# f28p65x_escss_regs register map
Vendor: Texas Instruments
Peripheral module from a debugger description file (folder C2000).
Address unit: 16 bits
Registers are 32-bit, read-write, no defined reset value unless marked. A register's access mark holds for its fields unless they carry their own. Offsets are as the file gives them; lines under a group give offsets from that group; [hi:lo] are bit positions; {n}, {i} and the like mark numbered series; 'fields as' and 'values as' point back to an identical list; <NAME> marks a mode.

## ESCSS_REGS — ESCSS Registers
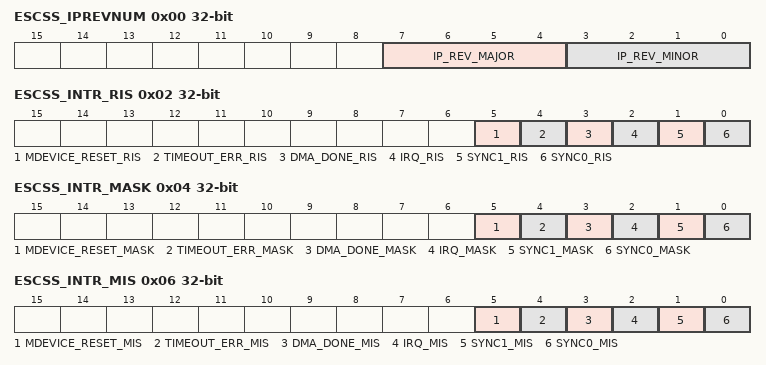
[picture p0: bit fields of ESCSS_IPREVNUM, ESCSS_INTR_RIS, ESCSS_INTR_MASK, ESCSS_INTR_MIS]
0x00 ESCSS_IPREVNUM ro — IP Revision Number
  [7:4] IP_REV_MAJOR — Major IP Revision Number
  [3:0] IP_REV_MINOR — Minor IP Revision Number
0x02 ESCSS_INTR_RIS ro — EtherCATSS Interrupt Raw Status
  [5] MDEVICE_RESET_RIS — ECAT RESET RIS
  [4] TIMEOUT_ERR_RIS — PDI bus Timeout Error RIS
  [3] DMA_DONE_RIS
  [2] IRQ_RIS — EtherCATSS IRQ RIS
  [1] SYNC1_RIS — SYNC1 feature RIS
  [0] SYNC0_RIS — SYNC0 feature RIS
0x04 ESCSS_INTR_MASK — EtherCATSS Interrupt Mask
  [5] MDEVICE_RESET_MASK — EtherCAT MainDevice Reset Mask
  [4] TIMEOUT_ERR_MASK — PDI Access Timeout Error Mask
  [3] DMA_DONE_MASK
  [2] IRQ_MASK — EtherCATSS IRQ Mask
  [1] SYNC1_MASK — SYNC1 feature Mask
  [0] SYNC0_MASK — SYNC0 feature Mask
0x06 ESCSS_INTR_MIS ro — EtherCATSS Masked Interrupt Status
  [5] MDEVICE_RESET_MIS — EtherCAT MainDevice Reset MIS
  [4] TIMEOUT_ERR_MIS — PDI bus Timeout Error MIS
  [3] DMA_DONE_MIS
  [2] IRQ_MIS — EtherCATSS IRQ MIS
  [1] SYNC1_MIS — SYNC1 feature MIS
  [0] SYNC0_MIS — SYNC0 feature MIS
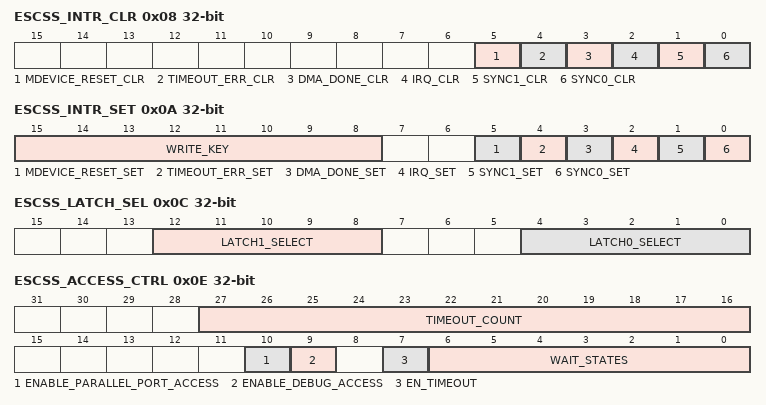
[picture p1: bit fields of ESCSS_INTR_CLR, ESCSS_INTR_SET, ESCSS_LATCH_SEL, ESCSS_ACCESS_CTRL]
0x08 ESCSS_INTR_CLR — EtherCATSS Interrupt Clear
  [5] MDEVICE_RESET_CLR — EtherCAT MainDevice Reset Clear
  [4] TIMEOUT_ERR_CLR — PDI Access Timeout Error Clear
  [3] DMA_DONE_CLR — DMA Done Clear
  [2] IRQ_CLR — EtherCATSS IRQ Clear
  [1] SYNC1_CLR — SYNC1 feature Clear
  [0] SYNC0_CLR — SYNC0 feature Clear
0x0A ESCSS_INTR_SET — EtherCATSS Interrupt Set to emulate
  [15:8] WRITE_KEY — Key to enable writing lock
  [5] MDEVICE_RESET_SET — EtherCAT MainDevice Reset Emulate
  [4] TIMEOUT_ERR_SET — PDI Access Timeout Error Set Emulate
  [3] DMA_DONE_SET — DMA Done Set Emulate
  [2] IRQ_SET — EtherCATSS IRQ Set Emulate
  [1] SYNC1_SET — SYNC1 Set Emulate
  [0] SYNC0_SET — SYNC0 Set Emulate
0x0C ESCSS_LATCH_SEL — Select for Latch0/1 inputs and LATCHIN input
  [12:8] LATCH1_SELECT — LATCH1 Inputs mux select
  [4:0] LATCH0_SELECT — LATCH0 Inputs mux select
0x0E ESCSS_ACCESS_CTRL — PDI interface access control config.
  [27:16] TIMEOUT_COUNT — Max timecount programmed and count while enabled.
  [10] ENABLE_PARALLEL_PORT_ACCESS — Parallel port access enable
  [9] ENABLE_DEBUG_ACCESS — Debug access enable
  [7] EN_TIMEOUT — PDI Timeout enable
  [6:0] WAIT_STATES — Minimum Wait States for VBUS Bridge
0x10 ESCSS_GPIN_DAT — GPIN data capture for debug and override
  [31:0] GPIN_DAT — Registered GPI data driving EtherCAT GPI input
0x12 ESCSS_GPIN_PIPE — GPIN pipeline select
  [31:0] GPI_PIPE — GPI IO inputs pipeline enable.
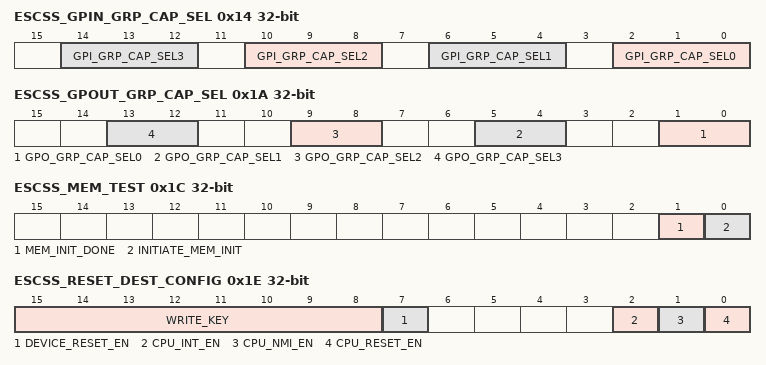
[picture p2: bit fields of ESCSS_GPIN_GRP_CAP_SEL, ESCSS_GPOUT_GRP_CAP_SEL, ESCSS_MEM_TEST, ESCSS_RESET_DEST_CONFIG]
0x14 ESCSS_GPIN_GRP_CAP_SEL — GPIN pipe group capture trigger
  [4n+2:4n] GPI_GRP_CAP_SEL{n} (n=0..3) — GPI{8n+7}-{8n} capture trigger select
0x16 ESCSS_GPOUT_DAT ro — GPOUT data capture for debug and override
  [31:0] GPOUT_DAT — Registered GPO data from EtherCAT o/p
0x18 ESCSS_GPOUT_PIPE — GPOUT pipeline select
  [31:0] GPO_PIPE — GPO output pipeline enable.
0x1A ESCSS_GPOUT_GRP_CAP_SEL — GPOUT pipe group capture trigger
  [4n+1:4n] GPO_GRP_CAP_SEL{n} (n=0..3) — GPO{8n+7}-{8n} capture trigger select
0x1C ESCSS_MEM_TEST access per field — Memory Test Control
  [1] MEM_INIT_DONE ro — Memory Init done status
  [0] INITIATE_MEM_INIT rw — Initialize memory init
0x1E ESCSS_RESET_DEST_CONFIG — ResetOut impact or destination config
  [15:8] WRITE_KEY — Key to enable writing lock
  [7] DEVICE_RESET_EN — Enables RESET_OUT to impact the device reset
  [2] CPU_INT_EN — CPU Interrupt enable for ResetOut
  [1] CPU_NMI_EN — CPU NMI enable for ResetOut
  [0] CPU_RESET_EN — CPU reset enable for ResetOut
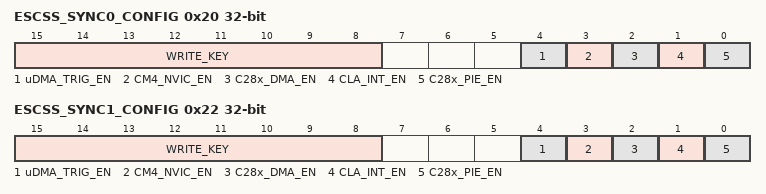
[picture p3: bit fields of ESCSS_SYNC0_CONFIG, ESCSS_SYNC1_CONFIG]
0x20 ESCSS_SYNC0_CONFIG — SYNC0 Configuration for various triggers
  [15:8] WRITE_KEY — Key to enable writing lock
  [4] uDMA_TRIG_EN — Connects the SYNC0 to uDMA Trigger
  [3] CM4_NVIC_EN — Connects the SYNC0 to CM4 NVIC Interrupt
  [2] C28x_DMA_EN — Connects the SYNC0 to C28x DMA Trigger
  [1] CLA_INT_EN — Connects the SYNC0 to CLA Interrupt
  [0] C28x_PIE_EN — Connects the SYNC0 to C28x PIE Interrupt
0x22 ESCSS_SYNC1_CONFIG — SYNC1 Configuration for various triggers
  [15:8] WRITE_KEY — Key to enable writing lock
  [4] uDMA_TRIG_EN — Connects the SYNC1 to uDMA Trigger
  [3] CM4_NVIC_EN — Connects the SYNC1 to CM4 NVIC Interrupt
  [2] C28x_DMA_EN — Connects the SYNC1 to C28x DMA Trigger
  [1] CLA_INT_EN — Connects the SYNC1 to CLA Interrupt
  [0] C28x_PIE_EN — Connects the SYNC1 to C28x PIE Interrupt
